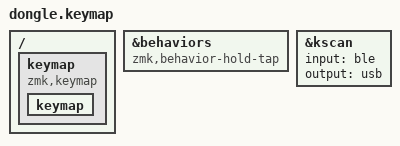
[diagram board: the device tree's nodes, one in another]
/ {
    keymap {
        compatible = "zmk,keymap";
        keymap {
            // ドングルはキー入力不要
        };
    };
};

&behaviors {
    compatible = "zmk,behavior-hold-tap";
};

&kscan {
    input = <&ble>;
    output = <&usb>;
};
